AUTOSAR XML (schema 4-0-3)
package /ComponentTypes
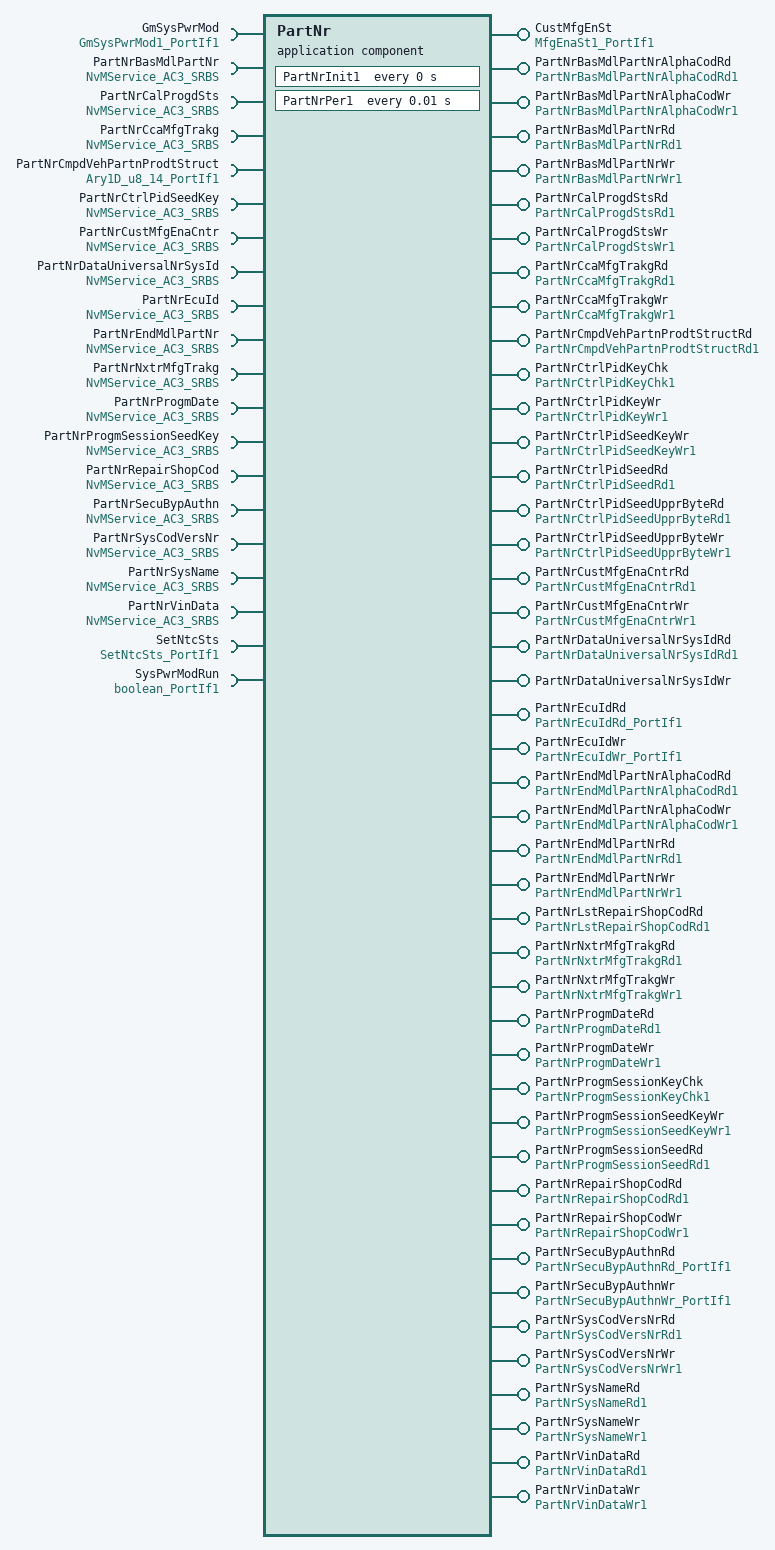
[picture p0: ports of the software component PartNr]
  application sw component type PartNr
    44 x provide port:
      CustMfgEnSt: nonqueued-sender-com-spec{data-element=Val, init-value=0}, provided-interface=MfgEnaSt1_PortIf1
      PartNrBasMdlPartNrAlphaCodRd: server-com-spec{operation=Oper, queue-length=1}, provided-interface=PartNrBasMdlPartNrAlphaCodRd1
      PartNrBasMdlPartNrAlphaCodWr: server-com-spec{operation=Oper, queue-length=1}, provided-interface=PartNrBasMdlPartNrAlphaCodWr1
      PartNrBasMdlPartNrRd: server-com-spec{operation=Oper, queue-length=1}, provided-interface=PartNrBasMdlPartNrRd1
      PartNrBasMdlPartNrWr: server-com-spec{operation=Oper, queue-length=1}, provided-interface=PartNrBasMdlPartNrWr1
      PartNrCalProgdStsRd: server-com-spec{operation=Oper, queue-length=1}, provided-interface=PartNrCalProgdStsRd1
      PartNrCalProgdStsWr: server-com-spec{operation=Oper, queue-length=1}, provided-interface=PartNrCalProgdStsWr1
      PartNrCcaMfgTrakgRd: server-com-spec{operation=Oper, queue-length=1}, provided-interface=PartNrCcaMfgTrakgRd1
      PartNrCcaMfgTrakgWr: server-com-spec{operation=Oper, queue-length=1}, provided-interface=PartNrCcaMfgTrakgWr1
      PartNrCmpdVehPartnProdtStructRd: server-com-spec{operation=Oper, queue-length=1}, provided-interface=PartNrCmpdVehPartnProdtStructRd1
      PartNrCtrlPidKeyChk: server-com-spec{operation=Oper, queue-length=1}, provided-interface=PartNrCtrlPidKeyChk1
      PartNrCtrlPidKeyWr: server-com-spec{operation=Oper, queue-length=1}, provided-interface=PartNrCtrlPidKeyWr1
      PartNrCtrlPidSeedKeyWr: server-com-spec{operation=Oper, queue-length=1}, provided-interface=PartNrCtrlPidSeedKeyWr1
      PartNrCtrlPidSeedRd: server-com-spec{operation=Oper, queue-length=1}, provided-interface=PartNrCtrlPidSeedRd1
      PartNrCtrlPidSeedUpprByteRd: server-com-spec{operation=Oper, queue-length=1}, provided-interface=PartNrCtrlPidSeedUpprByteRd1
      PartNrCtrlPidSeedUpprByteWr: server-com-spec{operation=Oper, queue-length=1}, provided-interface=PartNrCtrlPidSeedUpprByteWr1
      PartNrCustMfgEnaCntrRd: server-com-spec{operation=Oper, queue-length=1}, provided-interface=PartNrCustMfgEnaCntrRd1
      PartNrCustMfgEnaCntrWr: server-com-spec{operation=Oper, queue-length=1}, provided-interface=PartNrCustMfgEnaCntrWr1
      PartNrDataUniversalNrSysIdRd: server-com-spec{operation=Oper, queue-length=1}, provided-interface=PartNrDataUniversalNrSysIdRd1
      PartNrDataUniversalNrSysIdWr: server-com-spec{operation=Oper, queue-length=1}, provided-interface=PartNrDataUniversalNrSysIdWr
      PartNrEcuIdRd: server-com-spec{operation=Oper, queue-length=1}, provided-interface=PartNrEcuIdRd_PortIf1
      PartNrEcuIdWr: server-com-spec{operation=Oper, queue-length=1}, provided-interface=PartNrEcuIdWr_PortIf1
      PartNrEndMdlPartNrAlphaCodRd: server-com-spec{operation=Oper, queue-length=1}, provided-interface=PartNrEndMdlPartNrAlphaCodRd1
      PartNrEndMdlPartNrAlphaCodWr: server-com-spec{operation=Oper, queue-length=1}, provided-interface=PartNrEndMdlPartNrAlphaCodWr1
      PartNrEndMdlPartNrRd: server-com-spec{operation=Oper, queue-length=1}, provided-interface=PartNrEndMdlPartNrRd1
      PartNrEndMdlPartNrWr: server-com-spec{operation=Oper, queue-length=1}, provided-interface=PartNrEndMdlPartNrWr1
      PartNrLstRepairShopCodRd: server-com-spec{operation=Oper, queue-length=1}, provided-interface=PartNrLstRepairShopCodRd1
      PartNrNxtrMfgTrakgRd: server-com-spec{operation=Oper, queue-length=1}, provided-interface=PartNrNxtrMfgTrakgRd1
      PartNrNxtrMfgTrakgWr: server-com-spec{operation=Oper, queue-length=1}, provided-interface=PartNrNxtrMfgTrakgWr1
      PartNrProgmDateRd: server-com-spec{operation=Oper, queue-length=1}, provided-interface=PartNrProgmDateRd1
      PartNrProgmDateWr: server-com-spec{operation=Oper, queue-length=1}, provided-interface=PartNrProgmDateWr1
      PartNrProgmSessionKeyChk: server-com-spec{operation=Oper, queue-length=1}, provided-interface=PartNrProgmSessionKeyChk1
      PartNrProgmSessionSeedKeyWr: server-com-spec{operation=Oper, queue-length=1}, provided-interface=PartNrProgmSessionSeedKeyWr1
      PartNrProgmSessionSeedRd: server-com-spec{operation=Oper, queue-length=1}, provided-interface=PartNrProgmSessionSeedRd1
      PartNrRepairShopCodRd: server-com-spec{operation=Oper, queue-length=1}, provided-interface=PartNrRepairShopCodRd1
      PartNrRepairShopCodWr: server-com-spec{operation=Oper, queue-length=1}, provided-interface=PartNrRepairShopCodWr1
      PartNrSecuBypAuthnRd: server-com-spec{operation=Oper, queue-length=1}, provided-interface=PartNrSecuBypAuthnRd_PortIf1
      PartNrSecuBypAuthnWr: server-com-spec{operation=Oper, queue-length=1}, provided-interface=PartNrSecuBypAuthnWr_PortIf1
      PartNrSysCodVersNrRd: server-com-spec{operation=Oper, queue-length=1}, provided-interface=PartNrSysCodVersNrRd1
      PartNrSysCodVersNrWr: server-com-spec{operation=Oper, queue-length=1}, provided-interface=PartNrSysCodVersNrWr1
      PartNrSysNameRd: server-com-spec{operation=Oper, queue-length=1}, provided-interface=PartNrSysNameRd1
      PartNrSysNameWr: server-com-spec{operation=Oper, queue-length=1}, provided-interface=PartNrSysNameWr1
      PartNrVinDataRd: server-com-spec{operation=Oper, queue-length=1}, provided-interface=PartNrVinDataRd1
      PartNrVinDataWr: server-com-spec{operation=Oper, queue-length=1}, provided-interface=PartNrVinDataWr1
    20 x require port:
      GmSysPwrMod: nonqueued-receiver-com-spec{data-element=Val, filter=data-filter-type=ALWAYS, init-value=0}, required-interface=GmSysPwrMod1_PortIf1
      PartNrBasMdlPartNr: required-interface=NvMService_AC3_SRBS
      PartNrCalProgdSts: required-interface=NvMService_AC3_SRBS
      PartNrCcaMfgTrakg: required-interface=NvMService_AC3_SRBS
      PartNrCmpdVehPartnProdtStruct: parameter-require-com-spec{init-value=[56, 53, 57, 48, 50, 48, 48, 48, 48, 48, 48, 48, 48, 88], parameter=Ary1D}, required-interface=Ary1D_u8_14_PortIf1
      PartNrCtrlPidSeedKey: required-interface=NvMService_AC3_SRBS
      PartNrCustMfgEnaCntr: required-interface=NvMService_AC3_SRBS
      PartNrDataUniversalNrSysId: required-interface=NvMService_AC3_SRBS
      PartNrEcuId: required-interface=NvMService_AC3_SRBS
      PartNrEndMdlPartNr: required-interface=NvMService_AC3_SRBS
      PartNrNxtrMfgTrakg: required-interface=NvMService_AC3_SRBS
      PartNrProgmDate: required-interface=NvMService_AC3_SRBS
      PartNrProgmSessionSeedKey: required-interface=NvMService_AC3_SRBS
      PartNrRepairShopCod: required-interface=NvMService_AC3_SRBS
      PartNrSecuBypAuthn: required-interface=NvMService_AC3_SRBS
      PartNrSysCodVersNr: required-interface=NvMService_AC3_SRBS
      PartNrSysName: required-interface=NvMService_AC3_SRBS
      PartNrVinData: required-interface=NvMService_AC3_SRBS
      SetNtcSts: required-interface=SetNtcSts_PortIf1
      SysPwrModRun: nonqueued-receiver-com-spec{data-element=Logl, filter=data-filter-type=ALWAYS, init-value=0}, required-interface=boolean_PortIf1
    behavior PartNr_InternalBehavior
      ar-typed-per-instance-memorys:
        17 x data, all with sw-calibration-access=READ-ONLY:
          PartNrBasMdlPartNr: type=Ary1D_u8_6
          PartNrCalProgdSts: type=uint8
          PartNrCcaMfgTrakg: type=Ary1D_u8_9
          PartNrCtrlPidSeedKey: type=Ary1D_u8_10
          PartNrCustMfgEnaCntr: type=uint8
          PartNrDataUniversalNrSysId: type=Ary1D_u8_9
          PartNrEcuId: type=Ary1D_u8_16
          PartNrEndMdlPartNr: type=Ary1D_u8_6
          PartNrNxtrMfgTrakg: type=Ary1D_u8_7
          PartNrPrevSysPwrModRun: type=boolean
          PartNrProgmDate: type=Ary1D_u8_4
          PartNrProgmSessionSeedKey: type=Ary1D_u8_10
          PartNrRepairShopCod: type=Ary1D_u8_20
          PartNrSecuBypAuthn: type=Ary1D_u8_822
          PartNrSysCodVersNr: type=Ary1D_u8_2
          PartNrSysName: type=Ary1D_u8_20
          PartNrVinData: type=Ary1D_u8_17
      25 x operation invoked event:
        OIT_GmT1xxPartNrBasMdlPartNrAlphaCodRd_Oper_GmT1xxPartNrBasMdlPartNrAlphaCodRd_Oper: start-on-event=PartNrBasMdlPartNrAlphaCodRd_Oper, operation=PartNrBasMdlPartNrAlphaCodRd.Oper
        OIT_GmT1xxPartNrBasMdlPartNrAlphaCodWr_Oper_GmT1xxPartNrBasMdlPartNrAlphaCodWr_Oper: start-on-event=PartNrBasMdlPartNrAlphaCodWr_Oper, operation=PartNrBasMdlPartNrAlphaCodWr.Oper
        OIT_GmT1xxPartNrBasMdlPartNrRd_Oper_GmT1xxPartNrBasMdlPartNrRd_Oper: start-on-event=PartNrBasMdlPartNrRd_Oper, operation=PartNrBasMdlPartNrRd.Oper
        OIT_GmT1xxPartNrBasMdlPartNrWr_Oper_GmT1xxPartNrBasMdlPartNrWr_Oper: start-on-event=PartNrBasMdlPartNrWr_Oper, operation=PartNrBasMdlPartNrWr.Oper
        OIT_GmT1xxPartNrCalProgdStsRd_Oper_GmT1xxPartNrCalProgdStsRd_Oper: start-on-event=PartNrCalProgdStsRd_Oper, operation=PartNrCalProgdStsRd.Oper
        OIT_GmT1xxPartNrCalProgdStsWr_Oper_GmT1xxPartNrCalProgdStsWr_Oper: start-on-event=PartNrCalProgdStsWr_Oper, operation=PartNrCalProgdStsWr.Oper
        OIT_GmT1xxPartNrCcaMfgTrakgRd_Oper_GmT1xxPartNrCcaMfgTrakgRd_Oper: start-on-event=PartNrCcaMfgTrakgRd_Oper, operation=PartNrCcaMfgTrakgRd.Oper
        OIT_GmT1xxPartNrCcaMfgTrakgWr_Oper_GmT1xxPartNrCcaMfgTrakgWr_Oper: start-on-event=PartNrCcaMfgTrakgWr_Oper, operation=PartNrCcaMfgTrakgWr.Oper
        OIT_GmT1xxPartNrCmpdVehPartnProdtStructRd_Oper_GmT1xxPartNrCmpdVehPartnProdtStructRd_Oper: start-on-event=PartNrCmpdVehPartnProdtStructRd_Oper, operation=PartNrCmpdVehPartnProdtStructRd.Oper
        OIT_GmT1xxPartNrCtrlPidKeyChk_Oper_GmT1xxPartNrCtrlPidKeyChk_Oper: start-on-event=PartNrCtrlPidKeyChk_Oper, operation=PartNrCtrlPidKeyChk.Oper
        OIT_GmT1xxPartNrCtrlPidKeyWr_Oper_GmT1xxPartNrCtrlPidKeyWr_Oper: start-on-event=PartNrCtrlPidKeyWr_Oper, operation=PartNrCtrlPidKeyWr.Oper
        OIT_GmT1xxPartNrCtrlPidSeedKeyWr_Oper_GmT1xxPartNrCtrlPidSeedKeyWr_Oper: start-on-event=PartNrCtrlPidSeedKeyWr_Oper, operation=PartNrCtrlPidSeedKeyWr.Oper
        OIT_GmT1xxPartNrCtrlPidSeedRd_Oper_GmT1xxPartNrCtrlPidSeedRd_Oper: start-on-event=PartNrCtrlPidSeedRd_Oper, operation=PartNrCtrlPidSeedRd.Oper
        OIT_PartNrCtrlPidSeedUpprByteRd_Oper_PartNrCtrlPidSeedUpprByteRd_Oper: start-on-event=PartNrCtrlPidSeedUpprByteRd_Oper, operation=PartNrCtrlPidSeedUpprByteRd.Oper
        OIT_PartNrCtrlPidSeedUpprByteWr_Oper_PartNrCtrlPidSeedUpprByteWr_Oper: start-on-event=PartNrCtrlPidSeedUpprByteWr_Oper, operation=PartNrCtrlPidSeedUpprByteWr.Oper
        OIT_GmT1xxPartNrCustMfgEnaCntrRd_Oper_GmT1xxPartNrCustMfgEnaCntrRd_Oper: start-on-event=PartNrCustMfgEnaCntrRd_Oper, operation=PartNrCustMfgEnaCntrRd.Oper
        OIT_GmT1xxPartNrCustMfgEnaCntrWr_Oper_GmT1xxPartNrCustMfgEnaCntrWr_Oper: start-on-event=PartNrCustMfgEnaCntrWr_Oper, operation=PartNrCustMfgEnaCntrWr.Oper
        OIT_GmT1xxPartNrDataUniversalNrSysIdRd_Oper_GmT1xxPartNrDataUniversalNrSysIdRd_Oper: start-on-event=PartNrDataUniversalNrSysIdRd_Oper, operation=PartNrDataUniversalNrSysIdRd.Oper
        OIT_GmT1xxPartNrDataUniversalNrSysIdWr_Oper_GmT1xxPartNrDataUniversalNrSysIdWr_Oper: start-on-event=PartNrDataUniversalNrSysIdWr_Oper, operation=PartNrDataUniversalNrSysIdWr.Oper
        OIT_PartNrEcuIdRd_Oper_PartNrEcuIdRd_Oper: start-on-event=PartNrEcuIdRd_Oper, operation=PartNrEcuIdRd.Oper
        OIT_PartNrEcuIdWr_Oper_PartNrEcuIdWr_Oper: start-on-event=PartNrEcuIdWr_Oper, operation=PartNrEcuIdWr.Oper
        OIT_GmT1xxPartNrEndMdlPartNrAlphaCodRd_Oper_GmT1xxPartNrEndMdlPartNrAlphaCodRd_Oper: start-on-event=PartNrEndMdlPartNrAlphaCodRd_Oper, operation=PartNrEndMdlPartNrAlphaCodRd.Oper
        OIT_GmT1xxPartNrEndMdlPartNrAlphaCodWr_Oper_GmT1xxPartNrEndMdlPartNrAlphaCodWr_Oper: start-on-event=PartNrEndMdlPartNrAlphaCodWr_Oper, operation=PartNrEndMdlPartNrAlphaCodWr.Oper
        OIT_GmT1xxPartNrEndMdlPartNrRd_Oper_GmT1xxPartNrEndMdlPartNrRd_Oper: start-on-event=PartNrEndMdlPartNrRd_Oper, operation=PartNrEndMdlPartNrRd.Oper
        OIT_GmT1xxPartNrEndMdlPartNrWr_Oper_GmT1xxPartNrEndMdlPartNrWr_Oper: start-on-event=PartNrEndMdlPartNrWr_Oper, operation=PartNrEndMdlPartNrWr.Oper
      timing event PartNr_InitEvent: start-on-event=PartNrInit1, period=0
      operation invoked event OIT_GmT1xxPartNrLstRepairShopCodRd_Oper_GmT1xxPartNrLstRepairShopCodRd_Oper: start-on-event=PartNrLstRepairShopCodRd_Oper, operation=PartNrLstRepairShopCodRd.Oper
      operation invoked event OIT_GmT1xxPartNrNxtrMfgTrakgRd_Oper_GmT1xxPartNrNxtrMfgTrakgRd_Oper: start-on-event=PartNrNxtrMfgTrakgRd_Oper, operation=PartNrNxtrMfgTrakgRd.Oper
      operation invoked event OIT_GmT1xxPartNrNxtrMfgTrakgWr_Oper_GmT1xxPartNrNxtrMfgTrakgWr_Oper: start-on-event=PartNrNxtrMfgTrakgWr_Oper, operation=PartNrNxtrMfgTrakgWr.Oper
      timing event TMT_GmT1xxPartNrPer1: start-on-event=PartNrPer1, period=0.01
      15 x operation invoked event:
        OIT_GmT1xxPartNrProgmDateRd_Oper_GmT1xxPartNrProgmDateRd_Oper: start-on-event=PartNrProgmDateRd_Oper, operation=PartNrProgmDateRd.Oper
        OIT_GmT1xxPartNrProgmDateWr_Oper_GmT1xxPartNrProgmDateWr_Oper: start-on-event=PartNrProgmDateWr_Oper, operation=PartNrProgmDateWr.Oper
        OIT_GmT1xxPartNrProgmSessionKeyChk_Oper_GmT1xxPartNrProgmSessionKeyChk_Oper: start-on-event=PartNrProgmSessionKeyChk_Oper, operation=PartNrProgmSessionKeyChk.Oper
        OIT_GmT1xxPartNrProgmSessionSeedKeyWr_Ope_GmT1xxPartNrProgmSessionSeedKeyWr_Ope: start-on-event=PartNrProgmSessionSeedKeyWr_Oper, operation=PartNrProgmSessionSeedKeyWr.Oper
        OIT_GmT1xxPartNrProgmSessionSeedRd_Oper_GmT1xxPartNrProgmSessionSeedRd_Oper: start-on-event=PartNrProgmSessionSeedRd_Oper, operation=PartNrProgmSessionSeedRd.Oper
        OIT_GmT1xxPartNrRepairShopCodRd_Oper_GmT1xxPartNrRepairShopCodRd_Oper: start-on-event=PartNrRepairShopCodRd_Oper, operation=PartNrRepairShopCodRd.Oper
        OIT_GmT1xxPartNrRepairShopCodWr_Oper_GmT1xxPartNrRepairShopCodWr_Oper: start-on-event=PartNrRepairShopCodWr_Oper, operation=PartNrRepairShopCodWr.Oper
        OIT_PartNrSecuBypAuthnRd_Oper_PartNrSecuBypAuthnRd_Oper: start-on-event=PartNrSecuBypAuthnRd_Oper, operation=PartNrSecuBypAuthnRd.Oper
        OIT_PartNrSecuBypAuthnWr_Oper_PartNrSecuBypAuthnWr_Oper: start-on-event=PartNrSecuBypAuthnWr_Oper, operation=PartNrSecuBypAuthnWr.Oper
        OIT_GmT1xxPartNrSysCodVersNrRd_Oper_GmT1xxPartNrSysCodVersNrRd_Oper: start-on-event=PartNrSysCodVersNrRd_Oper, operation=PartNrSysCodVersNrRd.Oper
        OIT_GmT1xxPartNrSysCodVersNrWr_Oper_GmT1xxPartNrSysCodVersNrWr_Oper: start-on-event=PartNrSysCodVersNrWr_Oper, operation=PartNrSysCodVersNrWr.Oper
        OIT_GmT1xxPartNrSysNameRd_Oper_GmT1xxPartNrSysNameRd_Oper: start-on-event=PartNrSysNameRd_Oper, operation=PartNrSysNameRd.Oper
        OIT_GmT1xxPartNrSysNameWr_Oper_GmT1xxPartNrSysNameWr_Oper: start-on-event=PartNrSysNameWr_Oper, operation=PartNrSysNameWr.Oper
        OIT_GmT1xxPartNrVinDataRd_Oper_GmT1xxPartNrVinDataRd_Oper: start-on-event=PartNrVinDataRd_Oper, operation=PartNrVinDataRd.Oper
        OIT_GmT1xxPartNrVinDataWr_Oper_GmT1xxPartNrVinDataWr_Oper: start-on-event=PartNrVinDataWr_Oper, operation=PartNrVinDataWr.Oper
      45 x runnable:
        PartNrBasMdlPartNrAlphaCodRd_Oper: can-be-invoked-concurrently=true
        PartNrBasMdlPartNrAlphaCodWr_Oper: can-be-invoked-concurrently=true
          sync call SC_GmT1xxPartNrBasMdlPartNr_SetRamBlockStatus: operation=PartNrBasMdlPartNr.SetRamBlockStatus, timeout=0
        PartNrBasMdlPartNrRd_Oper: can-be-invoked-concurrently=true
        PartNrBasMdlPartNrWr_Oper: can-be-invoked-concurrently=true
          sync call SC_GmT1xxPartNrBasMdlPartNr_SetRamBlockStatus: operation=PartNrBasMdlPartNr.SetRamBlockStatus, timeout=0
        PartNrCalProgdStsRd_Oper: can-be-invoked-concurrently=true
        PartNrCalProgdStsWr_Oper: can-be-invoked-concurrently=true
          sync call SC_GmT1xxPartNrCalProgdSts_SetRamBlockStatus: operation=PartNrCalProgdSts.SetRamBlockStatus, timeout=0
        PartNrCcaMfgTrakgRd_Oper: can-be-invoked-concurrently=true
        PartNrCcaMfgTrakgWr_Oper: can-be-invoked-concurrently=true
          sync call SC_GmT1xxPartNrCcaMfgTrakg_SetRamBlockStatus: operation=PartNrCcaMfgTrakg.SetRamBlockStatus, timeout=0
        PartNrCmpdVehPartnProdtStructRd_Oper: can-be-invoked-concurrently=true
        PartNrCtrlPidKeyChk_Oper: can-be-invoked-concurrently=true
        PartNrCtrlPidKeyWr_Oper: can-be-invoked-concurrently=true
          sync call SC_PartNrCtrlPidSeedKey_SetRamBlockStatus: operation=PartNrCtrlPidSeedKey.SetRamBlockStatus, timeout=0
        PartNrCtrlPidSeedKeyWr_Oper: can-be-invoked-concurrently=true
          sync call SC_GmT1xxPartNrCtrlPidSeedKey_SetRamBlockStatus: operation=PartNrCtrlPidSeedKey.SetRamBlockStatus, timeout=0
        PartNrCtrlPidSeedRd_Oper: can-be-invoked-concurrently=true
        PartNrCtrlPidSeedUpprByteRd_Oper
        PartNrCtrlPidSeedUpprByteWr_Oper
          sync call SC_PartNrCtrlPidSeedKey_SetRamBlockStatus: operation=PartNrCtrlPidSeedKey.SetRamBlockStatus, timeout=0
        PartNrCustMfgEnaCntrRd_Oper: can-be-invoked-concurrently=true
        PartNrCustMfgEnaCntrWr_Oper: can-be-invoked-concurrently=true
          data-send-points:
            access SEND_CustMfgEnSt_Val: accessed-variable=CustMfgEnSt.Val
          sync call SC_GmT1xxPartNrCustMfgEnaCntr_SetRamBlockStatus: operation=PartNrCustMfgEnaCntr.SetRamBlockStatus, timeout=0
        PartNrDataUniversalNrSysIdRd_Oper: can-be-invoked-concurrently=true
        PartNrDataUniversalNrSysIdWr_Oper: can-be-invoked-concurrently=true
          sync call SC_GmT1xxPartNrDataUniversalNrSysId_SetRamBlockStatus: operation=PartNrDataUniversalNrSysId.SetRamBlockStatus, timeout=0
        PartNrEcuIdRd_Oper
        PartNrEcuIdWr_Oper
          sync call SC_PartNrEcuId_SetRamBlockStatus: operation=PartNrEcuId.SetRamBlockStatus, timeout=0
        PartNrEndMdlPartNrAlphaCodRd_Oper: can-be-invoked-concurrently=true
        PartNrEndMdlPartNrAlphaCodWr_Oper: can-be-invoked-concurrently=true
          sync call SC_GmT1xxPartNrEndMdlPartNr_SetRamBlockStatus: operation=PartNrEndMdlPartNr.SetRamBlockStatus, timeout=0
        PartNrEndMdlPartNrRd_Oper: can-be-invoked-concurrently=true
        PartNrEndMdlPartNrWr_Oper: can-be-invoked-concurrently=true
          sync call SC_GmT1xxPartNrEndMdlPartNr_SetRamBlockStatus: operation=PartNrEndMdlPartNr.SetRamBlockStatus, timeout=0
        PartNrInit1
          data-send-points:
            access SEND_CustMfgEnSt_Val: accessed-variable=CustMfgEnSt.Val
        PartNrLstRepairShopCodRd_Oper: can-be-invoked-concurrently=true
        PartNrNxtrMfgTrakgRd_Oper: can-be-invoked-concurrently=true
        PartNrNxtrMfgTrakgWr_Oper: can-be-invoked-concurrently=true
          sync call SC_GmT1xxPartNrNxtrMfgTrakg_SetRamBlockStatus: operation=PartNrNxtrMfgTrakg.SetRamBlockStatus, timeout=0
        PartNrPer1
          data-receive-point-by-arguments:
            access REC_GmSysPwrMod_Val: accessed-variable=GmSysPwrMod.Val
            access REC_SysPwrModRun_Logl: accessed-variable=SysPwrModRun.Logl
          data-send-points:
            access SEND_CustMfgEnSt_Val: accessed-variable=CustMfgEnSt.Val
          sync call SC_GmT1xxPartNrCustMfgEnaCntr_SetRamBlockStatus: operation=PartNrCustMfgEnaCntr.SetRamBlockStatus, timeout=0
          sync call SC_SetNtcSts_Oper: operation=SetNtcSts.Oper, timeout=0
        PartNrProgmDateRd_Oper: can-be-invoked-concurrently=true
        PartNrProgmDateWr_Oper: can-be-invoked-concurrently=true
          sync call SC_GmT1xxPartNrProgmDate_SetRamBlockStatus: operation=PartNrProgmDate.SetRamBlockStatus, timeout=0
        PartNrProgmSessionKeyChk_Oper: can-be-invoked-concurrently=true
        PartNrProgmSessionSeedKeyWr_Oper: can-be-invoked-concurrently=true
          sync call SC_GmT1xxPartNrProgmSessionSeedKey_SetRamBlockStatus: operation=PartNrProgmSessionSeedKey.SetRamBlockStatus, timeout=0
        PartNrProgmSessionSeedRd_Oper: can-be-invoked-concurrently=true
        PartNrRepairShopCodRd_Oper: can-be-invoked-concurrently=true
        PartNrRepairShopCodWr_Oper: can-be-invoked-concurrently=true
          sync call SC_GmT1xxPartNrRepairShopCod_SetRamBlockStatus: operation=PartNrRepairShopCod.SetRamBlockStatus, timeout=0
        PartNrSecuBypAuthnRd_Oper
        PartNrSecuBypAuthnWr_Oper
          sync call SC_PartNrSecuBypAuthn_SetRamBlockStatus: operation=PartNrSecuBypAuthn.SetRamBlockStatus, timeout=0
        PartNrSysCodVersNrRd_Oper: can-be-invoked-concurrently=true
        PartNrSysCodVersNrWr_Oper: can-be-invoked-concurrently=true
          sync call SC_GmT1xxPartNrSysCodVersNr_SetRamBlockStatus: operation=PartNrSysCodVersNr.SetRamBlockStatus, timeout=0
        PartNrSysNameRd_Oper: can-be-invoked-concurrently=true
        PartNrSysNameWr_Oper: can-be-invoked-concurrently=true
          sync call SC_GmT1xxPartNrSysName_SetRamBlockStatus: operation=PartNrSysName.SetRamBlockStatus, timeout=0
        PartNrVinDataRd_Oper: can-be-invoked-concurrently=true
        PartNrVinDataWr_Oper: can-be-invoked-concurrently=true
          sync call SC_GmT1xxPartNrVinData_SetRamBlockStatus: operation=PartNrVinData.SetRamBlockStatus, timeout=0
      16 x swc service dependency:
        NvmPartNrBasMdlPartNr
          assigned-datas:
            role=ramBlock, used-data-element=PartNrBasMdlPartNr
            role=defaultValue, used-parameter-element=PartNrBasMdlPartNrDft
          assigned-ports:
            port-prototype=PartNrBasMdlPartNr, role=NvMService_AC3_SRBS
            port-prototype=PartNrBasMdlPartNr, role=NvMService_AC3_SRBS
          service-needs:
            nv block needs NvmPartNrBasMdlPartNr: n-data-sets=0, readonly=false, reliability=NO-PROTECTION, resistant-to-changed-sw=true, restore-at-start=true, store-at-shutdown=true, write-only-once=false, writing-frequency=0, writing-priority=LOW
        NvmPartNrCalProgdSts
          assigned-datas:
            role=ramBlock, used-data-element=PartNrCalProgdSts
            role=defaultValue, used-parameter-element=PartNrCalProgdStsDft
          assigned-ports:
            port-prototype=PartNrCalProgdSts, role=NvMService_AC3_SRBS
            port-prototype=PartNrCalProgdSts, role=NvMService_AC3_SRBS
          service-needs:
            nv block needs NvmPartNrCalProgdSts: n-data-sets=0, readonly=false, reliability=NO-PROTECTION, resistant-to-changed-sw=true, restore-at-start=true, store-at-shutdown=true, write-only-once=false, writing-frequency=0, writing-priority=LOW
        NvmPartNrCcaMfgTrakg
          assigned-datas:
            role=ramBlock, used-data-element=PartNrCcaMfgTrakg
            role=defaultValue, used-parameter-element=PartNrCcaMfgTrakgDft
          assigned-ports:
            port-prototype=PartNrCcaMfgTrakg, role=NvMService_AC3_SRBS
            port-prototype=PartNrCcaMfgTrakg, role=NvMService_AC3_SRBS
          service-needs:
            nv block needs NvmPartNrCcaMfgTrakg: n-data-sets=0, readonly=false, reliability=NO-PROTECTION, resistant-to-changed-sw=true, restore-at-start=true, store-at-shutdown=true, write-only-once=false, writing-frequency=0, writing-priority=LOW
        NvmPartNrCtrlPidSeedKey
          assigned-datas:
            role=ramBlock, used-data-element=PartNrCtrlPidSeedKey
            role=defaultValue, used-parameter-element=PartNrCtrlPidSeedKeyDft
          assigned-ports:
            port-prototype=PartNrCtrlPidSeedKey, role=NvMService_AC3_SRBS
            port-prototype=PartNrCtrlPidSeedKey, role=NvMService_AC3_SRBS
          service-needs:
            nv block needs NvmPartNrCtrlPidSeedKey: n-data-sets=0, readonly=false, reliability=NO-PROTECTION, resistant-to-changed-sw=true, restore-at-start=true, store-at-shutdown=true, write-only-once=false, writing-frequency=0, writing-priority=LOW
        NvmPartNrCustMfgEnaCntr
          assigned-datas:
            role=ramBlock, used-data-element=PartNrCustMfgEnaCntr
            role=defaultValue, used-parameter-element=PartNrCustMfgEnaCntrDft
          assigned-ports:
            port-prototype=PartNrCustMfgEnaCntr, role=NvMService_AC3_SRBS
            port-prototype=PartNrCustMfgEnaCntr, role=NvMService_AC3_SRBS
          service-needs:
            nv block needs NvmPartNrCustMfgEnaCntr: n-data-sets=0, readonly=false, reliability=NO-PROTECTION, resistant-to-changed-sw=true, restore-at-start=true, store-at-shutdown=true, write-only-once=false, writing-frequency=0, writing-priority=LOW
        NvmPartNrDataUniversalNrSysId
          assigned-datas:
            role=ramBlock, used-data-element=PartNrDataUniversalNrSysId
            role=defaultValue, used-parameter-element=PartNrDataUniversalNrSysIdDft
          assigned-ports:
            port-prototype=PartNrDataUniversalNrSysId, role=NvMService_AC3_SRBS
            port-prototype=PartNrDataUniversalNrSysId, role=NvMService_AC3_SRBS
          service-needs:
            nv block needs NvmPartNrDataUniversalNrSysId: n-data-sets=0, readonly=false, reliability=NO-PROTECTION, resistant-to-changed-sw=true, restore-at-start=true, store-at-shutdown=true, write-only-once=false, writing-frequency=0, writing-priority=LOW
        NvmPartNrEcuId: assigned-datas=role-based-data-assignment={role=ramBlock, used-data-element=PartNrEcuId}
          assigned-ports:
            port-prototype=PartNrEcuId, role=NvMService_AC3_SRBS
            port-prototype=PartNrEcuId, role=NvMService_AC3_SRBS
          service-needs:
            nv block needs NvmPartNrEcuId: n-data-sets=0, readonly=false, reliability=NO-PROTECTION, resistant-to-changed-sw=true, restore-at-start=true, store-at-shutdown=true, write-only-once=false
        NvmPartNrEndMdlPartNr
          assigned-datas:
            role=ramBlock, used-data-element=PartNrEndMdlPartNr
            role=defaultValue, used-parameter-element=PartNrEndMdlPartNrDft
          assigned-ports:
            port-prototype=PartNrEndMdlPartNr, role=NvMService_AC3_SRBS
            port-prototype=PartNrEndMdlPartNr, role=NvMService_AC3_SRBS
          service-needs:
            nv block needs NvmPartNrEndMdlPartNr: n-data-sets=0, readonly=false, reliability=NO-PROTECTION, resistant-to-changed-sw=true, restore-at-start=true, store-at-shutdown=true, write-only-once=false, writing-frequency=0, writing-priority=LOW
        NvmPartNrNxtrMfgTrakg
          assigned-datas:
            role=ramBlock, used-data-element=PartNrNxtrMfgTrakg
            role=defaultValue, used-parameter-element=PartNrNxtrMfgTrakgDft
          assigned-ports:
            port-prototype=PartNrNxtrMfgTrakg, role=NvMService_AC3_SRBS
            port-prototype=PartNrNxtrMfgTrakg, role=NvMService_AC3_SRBS
          service-needs:
            nv block needs NvmPartNrNxtrMfgTrakg: n-data-sets=0, readonly=false, reliability=NO-PROTECTION, resistant-to-changed-sw=true, restore-at-start=true, store-at-shutdown=true, write-only-once=false, writing-frequency=0, writing-priority=LOW
        NvmPartNrProgmDate
          assigned-datas:
            role=ramBlock, used-data-element=PartNrProgmDate
            role=defaultValue, used-parameter-element=PartNrProgmDateDft
          assigned-ports:
            port-prototype=PartNrProgmDate, role=NvMService_AC3_SRBS
            port-prototype=PartNrProgmDate, role=NvMService_AC3_SRBS
          service-needs:
            nv block needs NvmPartNrProgmDate: n-data-sets=0, readonly=false, reliability=NO-PROTECTION, resistant-to-changed-sw=true, restore-at-start=true, store-at-shutdown=true, write-only-once=false, writing-frequency=0, writing-priority=LOW
        NvmPartNrProgmSessionSeedKey
          assigned-datas:
            role=ramBlock, used-data-element=PartNrProgmSessionSeedKey
            role=defaultValue, used-parameter-element=PartNrProgmSessionSeedKeyDft
          assigned-ports:
            port-prototype=PartNrProgmSessionSeedKey, role=NvMService_AC3_SRBS
            port-prototype=PartNrProgmSessionSeedKey, role=NvMService_AC3_SRBS
          service-needs:
            nv block needs NvmPartNrProgmSessionSeedKey: n-data-sets=0, readonly=false, reliability=NO-PROTECTION, resistant-to-changed-sw=true, restore-at-start=true, store-at-shutdown=true, write-only-once=false, writing-frequency=0, writing-priority=LOW
        NvmPartNrRepairShopCod
          assigned-datas:
            role=ramBlock, used-data-element=PartNrRepairShopCod
            role=defaultValue, used-parameter-element=PartNrRepairShopCodDft
          assigned-ports:
            port-prototype=PartNrRepairShopCod, role=NvMService_AC3_SRBS
            port-prototype=PartNrRepairShopCod, role=NvMService_AC3_SRBS
          service-needs:
            nv block needs NvmPartNrRepairShopCod: n-data-sets=0, readonly=false, reliability=NO-PROTECTION, resistant-to-changed-sw=true, restore-at-start=true, store-at-shutdown=true, write-only-once=false, writing-frequency=0, writing-priority=LOW
        NvmPartNrSecuBypAuthn: assigned-datas=role-based-data-assignment={role=ramBlock, used-data-element=PartNrSecuBypAuthn}
          assigned-ports:
            port-prototype=PartNrSecuBypAuthn, role=NvMService_AC3_SRBS
            port-prototype=PartNrSecuBypAuthn, role=NvMService_AC3_SRBS
          service-needs:
            nv block needs NvmPartNrSecuBypAuthn: n-data-sets=0, readonly=false, reliability=NO-PROTECTION, resistant-to-changed-sw=true, restore-at-start=true, store-at-shutdown=true, write-only-once=false
        NvmPartNrSysCodVersNr
          assigned-datas:
            role=ramBlock, used-data-element=PartNrSysCodVersNr
            role=defaultValue, used-parameter-element=PartNrSysCodVersNrDft
          assigned-ports:
            port-prototype=PartNrSysCodVersNr, role=NvMService_AC3_SRBS
            port-prototype=PartNrSysCodVersNr, role=NvMService_AC3_SRBS
          service-needs:
            nv block needs NvmPartNrSysCodVersNr: n-data-sets=0, readonly=false, reliability=NO-PROTECTION, resistant-to-changed-sw=true, restore-at-start=true, store-at-shutdown=true, write-only-once=false, writing-frequency=0, writing-priority=LOW
        NvmPartNrSysName
          assigned-datas:
            role=ramBlock, used-data-element=PartNrSysName
            role=defaultValue, used-parameter-element=PartNrSysNameDft
          assigned-ports:
            port-prototype=PartNrSysName, role=NvMService_AC3_SRBS
            port-prototype=PartNrSysName, role=NvMService_AC3_SRBS
          service-needs:
            nv block needs NvmPartNrSysName: n-data-sets=0, readonly=false, reliability=NO-PROTECTION, resistant-to-changed-sw=true, restore-at-start=true, store-at-shutdown=true, write-only-once=false, writing-frequency=0, writing-priority=LOW
        NvmPartNrVinData
          assigned-datas:
            role=ramBlock, used-data-element=PartNrVinData
            role=defaultValue, used-parameter-element=PartNrVinDataDft
          assigned-ports:
            port-prototype=PartNrVinData, role=NvMService_AC3_SRBS
            port-prototype=PartNrVinData, role=NvMService_AC3_SRBS
          service-needs:
            nv block needs NvmPartNrVinData: n-data-sets=0, readonly=false, reliability=NO-PROTECTION, resistant-to-changed-sw=true, restore-at-start=true, store-at-shutdown=true, write-only-once=false, writing-frequency=0, writing-priority=LOW
      shared-parameters:
        14 x parameter data prototype, all with sw-calibration-access=READ-WRITE:
          PartNrBasMdlPartNrDft: type=Ary1D_u8_6, init-value=6 x 0
          PartNrCalProgdStsDft: type=uint8, init-value=170
          PartNrCcaMfgTrakgDft: type=Ary1D_u8_9, init-value=9 x 0
          PartNrCtrlPidSeedKeyDft: type=Ary1D_u8_10, init-value=[1, 2, 3, 4, 5, 254, 253, 252, 251, 250]
          PartNrCustMfgEnaCntrDft: type=uint8, init-value=254
          PartNrDataUniversalNrSysIdDft: type=Ary1D_u8_9, init-value=[48, 53, 51, 51, 51, 51, 48, 53, 53]
          PartNrEndMdlPartNrDft: type=Ary1D_u8_6, init-value=6 x 0
          PartNrNxtrMfgTrakgDft: type=Ary1D_u8_7, init-value=7 x 0
          PartNrProgmDateDft: type=Ary1D_u8_4, init-value=[0, 0, 0, 0]
          PartNrProgmSessionSeedKeyDft: type=Ary1D_u8_10, init-value=[1, 2, 3, 4, 5, 254, 253, 252, 251, 250]
          PartNrRepairShopCodDft: type=Ary1D_u8_20, init-value=20 x 48
          PartNrSysCodVersNrDft: type=Ary1D_u8_2, init-value=[18, 1]
          PartNrSysNameDft: type=Ary1D_u8_20, init-value=[82, 65, 67, 75, 45, 69, 80, 83, 0, 0, 0, 0, 0, 0, 0, 0, 0, 0, 0, 0]
          PartNrVinDataDft: type=Ary1D_u8_17, init-value=17 x 0
  swc implementation PartNr_Implementation: behavior=PartNr_InternalBehavior
    code-descriptors:
      code Default: artifact-descriptors=autosar-engineering-object={short-label=Default, category=SWSRC}
